AUTOSAR XML (schema 4-2-2)
package /STELLANTIS/EPT/ASWCs
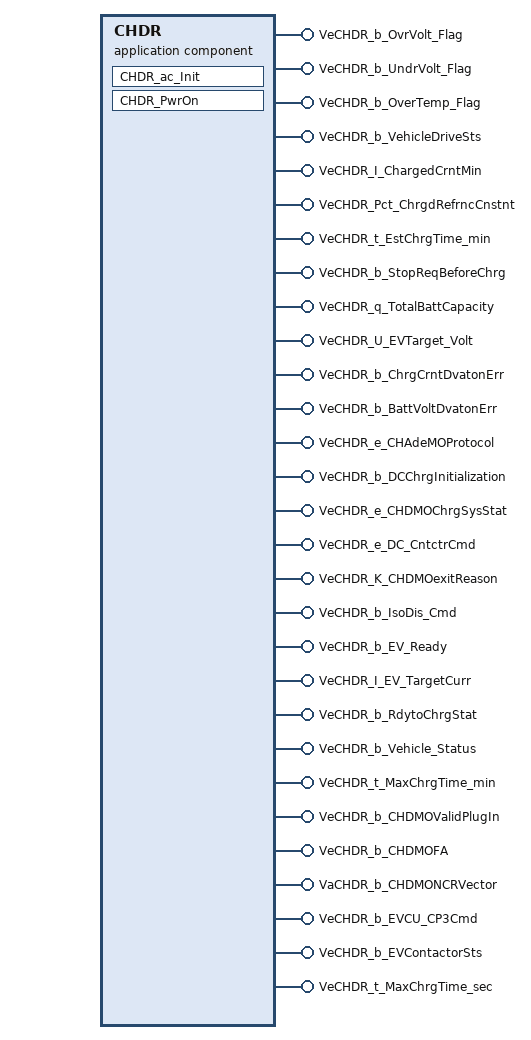
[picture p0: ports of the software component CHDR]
  application sw component type CHDR
    29 x provide port:
      VeCHDR_b_OvrVolt_Flag: nonqueued-sender-com-spec{data-element=Value, init-value=0}, provided-interface=VeCHDR_b_OvrVolt_Flag
      VeCHDR_b_UndrVolt_Flag: nonqueued-sender-com-spec{data-element=Value, init-value=0}, provided-interface=VeCHDR_b_UndrVolt_Flag
      VeCHDR_b_OverTemp_Flag: nonqueued-sender-com-spec{data-element=Value, init-value=0}, provided-interface=VeCHDR_b_OverTemp_Flag
      VeCHDR_b_VehicleDriveSts: nonqueued-sender-com-spec{data-element=Value, init-value=0}, provided-interface=VeCHDR_b_VehicleDriveSts
      VeCHDR_I_ChargedCrntMin: nonqueued-sender-com-spec{data-element=Value, init-value=0}, provided-interface=VeCHDR_I_ChargedCrntMin
      VeCHDR_Pct_ChrgdRefrncCnstnt: nonqueued-sender-com-spec{data-element=Value, init-value=0}, provided-interface=VeCHDR_Pct_ChrgdRefrncCnstnt
      VeCHDR_t_EstChrgTime_min: nonqueued-sender-com-spec{data-element=Value, init-value=0}, provided-interface=VeCHDR_t_EstChrgTime_min
      VeCHDR_b_StopReqBeforeChrg: nonqueued-sender-com-spec{data-element=Value, init-value=0}, provided-interface=VeCHDR_b_StopReqBeforeChrg
      VeCHDR_q_TotalBattCapacity: nonqueued-sender-com-spec{data-element=Value, init-value=0}, provided-interface=VeCHDR_q_TotalBattCapacity
      VeCHDR_U_EVTarget_Volt: nonqueued-sender-com-spec{data-element=Value, init-value=0}, provided-interface=VeCHDR_U_EVTarget_Volt
      VeCHDR_b_ChrgCrntDvatonErr: nonqueued-sender-com-spec{data-element=Value, init-value=0}, provided-interface=VeCHDR_b_ChrgCrntDvatonErr
      VeCHDR_b_BattVoltDvatonErr: nonqueued-sender-com-spec{data-element=Value, init-value=0}, provided-interface=VeCHDR_b_BattVoltDvatonErr
      VeCHDR_e_CHAdeMOProtocol: nonqueued-sender-com-spec{data-element=Value, init-value=CeIDCR_e_CHAdeMO_0_9_n_earlier}, provided-interface=VeCHDR_e_CHAdeMOProtocol
      VeCHDR_b_DCChrgInitialization: nonqueued-sender-com-spec{data-element=Value, init-value=0}, provided-interface=VeCHDR_b_DCChrgInitialization
      VeCHDR_e_CHDMOChrgSysStat: nonqueued-sender-com-spec{data-element=Value, init-value=CeCHDR_e_CHDMOinit}, provided-interface=VeCHDR_e_CHDMOChrgSysStat
      VeCHDR_e_DC_CntctrCmd: nonqueued-sender-com-spec{data-element=Value, init-value=CeOBCR_e_DCCntctr_Open}, provided-interface=VeCHDR_e_DC_CntctrCmd
      VeCHDR_K_CHDMOexitReason: nonqueued-sender-com-spec{data-element=Value, init-value=0}, provided-interface=VeCHDR_K_CHDMOexitReason
      VeCHDR_b_IsoDis_Cmd: nonqueued-sender-com-spec{data-element=Value, init-value=0}, provided-interface=VeCHDR_b_IsoDis_Cmd
      VeCHDR_b_EV_Ready: nonqueued-sender-com-spec{data-element=Value, init-value=0}, provided-interface=VeCHDR_b_EV_Ready
      VeCHDR_I_EV_TargetCurr: nonqueued-sender-com-spec{data-element=Value, init-value=0}, provided-interface=VeCHDR_I_EV_TargetCurr
      VeCHDR_b_RdytoChrgStat: nonqueued-sender-com-spec{data-element=Value, init-value=0}, provided-interface=VeCHDR_b_RdytoChrgStat
      VeCHDR_b_Vehicle_Status: nonqueued-sender-com-spec{data-element=Value, init-value=0}, provided-interface=VeCHDR_b_Vehicle_Status
      VeCHDR_t_MaxChrgTime_min: nonqueued-sender-com-spec{data-element=Value, init-value=0}, provided-interface=VeCHDR_t_MaxChrgTime_min
      VeCHDR_b_CHDMOValidPlugIn: nonqueued-sender-com-spec{data-element=Value, init-value=0}, provided-interface=VeCHDR_b_CHDMOValidPlugIn
      VeCHDR_b_CHDMOFA: nonqueued-sender-com-spec{data-element=Value, init-value=0}, provided-interface=VeCHDR_b_CHDMOFA
      VaCHDR_b_CHDMONCRVector: nonqueued-sender-com-spec{data-element=Value, init-value=[0, 0, 0, 0]}, provided-interface=VaCHDR_b_CHDMONCRVector
      VeCHDR_b_EVCU_CP3Cmd: nonqueued-sender-com-spec{data-element=Value, init-value=0}, provided-interface=VeCHDR_b_EVCU_CP3Cmd
      VeCHDR_b_EVContactorSts: nonqueued-sender-com-spec{data-element=Value, init-value=0}, provided-interface=VeCHDR_b_EVContactorSts
      VeCHDR_t_MaxChrgTime_sec: nonqueued-sender-com-spec{data-element=Value, init-value=0}, provided-interface=VeCHDR_t_MaxChrgTime_sec
    behavior IB_CHDR: data-type-mapping=msADTtoIDTMapping, handle-termination-and-restart=NO-SUPPORT
      init event Event_CHDR_ac_Init: start-on-event=CHDR_ac_Init
      init event Event_PwrOn: start-on-event=CHDR_PwrOn
      runnable CHDR_ac_Init
        data-send-points:
          4 x access:
            OUT_VeCHDR_e_CHAdeMOProtocol_Value: accessed-variable=VeCHDR_e_CHAdeMOProtocol.Value
            OUT_VeCHDR_e_CHDMOChrgSysStat_Value: accessed-variable=VeCHDR_e_CHDMOChrgSysStat.Value
            OUT_VeCHDR_e_DC_CntctrCmd_Value: accessed-variable=VeCHDR_e_DC_CntctrCmd.Value
            OUT_VaCHDR_b_CHDMONCRVector_Value: accessed-variable=VaCHDR_b_CHDMONCRVector.Value
      runnable CHDR_PwrOn
        data-send-points:
          29 x access:
            OUT_VeCHDR_b_OvrVolt_Flag_Value: accessed-variable=VeCHDR_b_OvrVolt_Flag.Value
            OUT_VeCHDR_b_UndrVolt_Flag_Value: accessed-variable=VeCHDR_b_UndrVolt_Flag.Value
            OUT_VeCHDR_b_OverTemp_Flag_Value: accessed-variable=VeCHDR_b_OverTemp_Flag.Value
            OUT_VeCHDR_b_VehicleDriveSts_Value: accessed-variable=VeCHDR_b_VehicleDriveSts.Value
            OUT_VeCHDR_I_ChargedCrntMin_Value: accessed-variable=VeCHDR_I_ChargedCrntMin.Value
            OUT_VeCHDR_Pct_ChrgdRefrncCnstnt_Value: accessed-variable=VeCHDR_Pct_ChrgdRefrncCnstnt.Value
            OUT_VeCHDR_t_EstChrgTime_min_Value: accessed-variable=VeCHDR_t_EstChrgTime_min.Value
            OUT_VeCHDR_b_StopReqBeforeChrg_Value: accessed-variable=VeCHDR_b_StopReqBeforeChrg.Value
            OUT_VeCHDR_q_TotalBattCapacity_Value: accessed-variable=VeCHDR_q_TotalBattCapacity.Value
            OUT_VeCHDR_U_EVTarget_Volt_Value: accessed-variable=VeCHDR_U_EVTarget_Volt.Value
            OUT_VeCHDR_b_ChrgCrntDvatonErr_Value: accessed-variable=VeCHDR_b_ChrgCrntDvatonErr.Value
            OUT_VeCHDR_b_BattVoltDvatonErr_Value: accessed-variable=VeCHDR_b_BattVoltDvatonErr.Value
            OUT_VeCHDR_e_CHAdeMOProtocol_Value: accessed-variable=VeCHDR_e_CHAdeMOProtocol.Value
            OUT_VeCHDR_b_DCChrgInitialization_Value: accessed-variable=VeCHDR_b_DCChrgInitialization.Value
            OUT_VeCHDR_e_CHDMOChrgSysStat_Value: accessed-variable=VeCHDR_e_CHDMOChrgSysStat.Value
            OUT_VeCHDR_e_DC_CntctrCmd_Value: accessed-variable=VeCHDR_e_DC_CntctrCmd.Value
            OUT_VeCHDR_K_CHDMOexitReason_Value: accessed-variable=VeCHDR_K_CHDMOexitReason.Value
            OUT_VeCHDR_b_IsoDis_Cmd_Value: accessed-variable=VeCHDR_b_IsoDis_Cmd.Value
            OUT_VeCHDR_b_EV_Ready_Value: accessed-variable=VeCHDR_b_EV_Ready.Value
            OUT_VeCHDR_I_EV_TargetCurr_Value: accessed-variable=VeCHDR_I_EV_TargetCurr.Value
            OUT_VeCHDR_b_RdytoChrgStat_Value: accessed-variable=VeCHDR_b_RdytoChrgStat.Value
            OUT_VeCHDR_b_Vehicle_Status_Value: accessed-variable=VeCHDR_b_Vehicle_Status.Value
            OUT_VeCHDR_t_MaxChrgTime_min_Value: accessed-variable=VeCHDR_t_MaxChrgTime_min.Value
            OUT_VeCHDR_t_MaxChrgTime_sec_Value: accessed-variable=VeCHDR_t_MaxChrgTime_sec.Value
            OUT_VeCHDR_b_CHDMOValidPlugIn_Value: accessed-variable=VeCHDR_b_CHDMOValidPlugIn.Value
            OUT_VeCHDR_b_CHDMOFA_Value: accessed-variable=VeCHDR_b_CHDMOFA.Value
            OUT_VaCHDR_b_CHDMONCRVector_Value: accessed-variable=VaCHDR_b_CHDMONCRVector.Value
            OUT_VeCHDR_b_EVCU_CP3Cmd_Value: accessed-variable=VeCHDR_b_EVCU_CP3Cmd.Value
            OUT_VeCHDR_b_EVContactorSts_Value: accessed-variable=VeCHDR_b_EVContactorSts.Value
      variation point proxy Variant_CHDR_FUNC: category=CONDITION, condition-access=0
